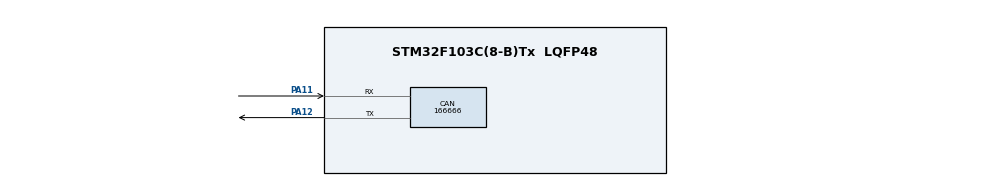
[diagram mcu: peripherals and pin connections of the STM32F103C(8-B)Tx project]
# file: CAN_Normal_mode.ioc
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CAN.CalculateBaudRate=166666
CAN.CalculateTimeBit=6000.00
CAN.CalculateTimeQuantum=2000.0
Mcu.Family=STM32F1
Mcu.Name=STM32F103C(8-B)Tx
Mcu.Package=LQFP48
NVIC.PriorityGroup=NVIC_PRIORITYGROUP_4
NVIC.TIM4_IRQn=true\:15\:0\:true\:false\:true\:true\:true
PA11.Mode=CAN_Activate
PA11.Signal=CAN_RX
PA12.Mode=CAN_Activate
PA12.Signal=CAN_TX
PA13.Mode=Serial_Wire
PA13.Signal=SYS_JTMS-SWDIO
PA14.Mode=Serial_Wire
PA14.Signal=SYS_JTCK-SWCLK
PC14-OSC32_IN.Mode=LSE-External-Oscillator
PC14-OSC32_IN.Signal=RCC_OSC32_IN
PC15-OSC32_OUT.Mode=LSE-External-Oscillator
PC15-OSC32_OUT.Signal=RCC_OSC32_OUT
PD0-OSC_IN.Mode=HSE-External-Oscillator
PD0-OSC_IN.Signal=RCC_OSC_IN
PD1-OSC_OUT.Mode=HSE-External-Oscillator
PD1-OSC_OUT.Signal=RCC_OSC_OUT
ProjectManager.HeapSize=0x200
ProjectManager.StackSize=0x400
ProjectManager.TargetToolchain=MDK-ARM V5.27
RCC.APB1Freq_Value=8000000
RCC.APB2Freq_Value=8000000
RCC.SYSCLKSource=RCC_SYSCLKSOURCE_HSE
TIM4.AutoReloadPreload=TIM_AUTORELOAD_PRELOAD_ENABLE
TIM4.Period=99
TIM4.Prescaler=7999
VP_TIM4_VS_ClockSourceINT.Mode=Internal
board=custom

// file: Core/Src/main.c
/* USER CODE BEGIN Header */
/**
  ******************************************************************************
  * @file           : main.c
  * @brief          : Main program body
  ******************************************************************************
  * @attention
  *
  * <h2><center>&copy; Copyright (c) 2021 STMicroelectronics.
  * All rights reserved.</center></h2>
  *
  * This software component is licensed by ST under BSD 3-Clause license,
  * the "License"; You may not use this file except in compliance with the
  * License. You may obtain a copy of the License at:
  *                        opensource.org/licenses/BSD-3-Clause
  *
  ******************************************************************************
  */
/* USER CODE END Header */
#include "main.h"
#include "can.h"
#include "tim.h"
#include "gpio.h"

/* USER CODE BEGIN PV */
volatile float g_timer_count = 0u;
volatile uint8_t led_no = 0u;
/* USER CODE END PV */

void SystemClock_Config(void);
/* USER CODE BEGIN PFP */
HAL_StatusTypeDef CAN_Transmit(void);
HAL_StatusTypeDef CAN_Filter_Config( void );
HAL_StatusTypeDef LED_manage_output( uint8_t led_no );
HAL_StatusTypeDef Send_response( uint32_t SidId );
HAL_StatusTypeDef CAN_Transmit_request(void);
/* USER CODE END PFP */

int main(void)
{

  /* MCU Configuration--------------------------------------------------------*/

  /* Reset of all peripherals, Initializes the Flash interface and the Systick. */
  HAL_Init();

  /* Configure the system clock */
  SystemClock_Config();

  /* Initialize all configured peripherals */
  MX_GPIO_Init();
  MX_CAN_Init();
  MX_TIM4_Init();
  /* USER CODE BEGIN 2 */
	HAL_TIM_Base_Start_IT(&htim4);

	CAN_Filter_Config();
	if( HAL_OK != HAL_CAN_ActivateNotification(&hcan, CAN_IT_TX_MAILBOX_EMPTY | CAN_IT_RX_FIFO0_MSG_PENDING | CAN_IT_BUSOFF)){
		Error_Handler();
	}
	if( HAL_OK != HAL_CAN_Start(&hcan)){ // put can in normal mode
		Error_Handler();
	}

  /* USER CODE END 2 */

  /* Infinite loop */
  while (1)
  {

  }
}

void SystemClock_Config(void)
{
  RCC_OscInitTypeDef RCC_OscInitStruct = {0};
  RCC_ClkInitTypeDef RCC_ClkInitStruct = {0};

  /** Initializes the RCC Oscillators according to the specified parameters
  * in the RCC_OscInitTypeDef structure.
  */
  RCC_OscInitStruct.OscillatorType = RCC_OSCILLATORTYPE_HSE;
  RCC_OscInitStruct.HSEState = RCC_HSE_ON;
  RCC_OscInitStruct.PLL.PLLState = RCC_PLL_NONE;
  if (HAL_RCC_OscConfig(&RCC_OscInitStruct) != HAL_OK)
  {
    Error_Handler();
  }
  /** Initializes the CPU, AHB and APB buses clocks
  */
  RCC_ClkInitStruct.ClockType = RCC_CLOCKTYPE_HCLK|RCC_CLOCKTYPE_SYSCLK
                              |RCC_CLOCKTYPE_PCLK1|RCC_CLOCKTYPE_PCLK2;
  RCC_ClkInitStruct.SYSCLKSource = RCC_SYSCLKSOURCE_HSE;
  RCC_ClkInitStruct.AHBCLKDivider = RCC_SYSCLK_DIV1;
  RCC_ClkInitStruct.APB1CLKDivider = RCC_HCLK_DIV1;
  RCC_ClkInitStruct.APB2CLKDivider = RCC_HCLK_DIV1;

  if (HAL_RCC_ClockConfig(&RCC_ClkInitStruct, FLASH_LATENCY_0) != HAL_OK)
  {
    Error_Handler();
  }

}

/* USER CODE BEGIN 4 */
void HAL_TIM_PeriodElapsedCallback(TIM_HandleTypeDef *htim)
{
  if( htim == &htim4 ){
		g_timer_count += 1u;
		if( 4u == g_timer_count){
			CAN_Transmit_request();
		}
		else{
			CAN_Transmit();
		}
	}
}

HAL_StatusTypeDef CAN_Transmit_request(void){
	uint8_t msg= 0u; // no meaning for data frame
	uint32_t mail_box;

	CAN_TxHeaderTypeDef Tx_header;
	Tx_header.DLC = 2u; // note(sender) request the receiver send 2bytes of reply
	Tx_header.IDE = CAN_ID_STD;
	Tx_header.StdId = 0x651;
	Tx_header.RTR = CAN_RTR_REMOTE;

	if( HAL_OK != HAL_CAN_AddTxMessage(&hcan, &Tx_header, &msg, &mail_box)){
		Error_Handler();
	}

	return HAL_OK;
}

HAL_StatusTypeDef CAN_Transmit(void){
	uint8_t msg= ++led_no;
	uint32_t mail_box;

	CAN_TxHeaderTypeDef Tx_header;
	Tx_header.DLC = 1u; // Transmit one bytes
	Tx_header.IDE = CAN_ID_STD;
	Tx_header.StdId = 0x65D;
	Tx_header.RTR = CAN_RTR_DATA;

	if( HAL_OK != HAL_CAN_AddTxMessage(&hcan, &Tx_header, &msg, &mail_box)){
		Error_Handler();
	}

	return HAL_OK;
}

HAL_StatusTypeDef CAN_Filter_Config( void ){
	CAN_FilterTypeDef Rx_filter_init;

	Rx_filter_init.FilterActivation = ENABLE;
	Rx_filter_init.FilterBank = 0U;
	Rx_filter_init.FilterFIFOAssignment = CAN_RX_FIFO0;
	Rx_filter_init.FilterIdHigh = 0x0000;
	Rx_filter_init.FilterIdLow = 0x0000;
	Rx_filter_init.FilterMaskIdHigh = 0x0000;
	Rx_filter_init.FilterMaskIdLow = 0x0000;
	Rx_filter_init.FilterMode = CAN_FILTERMODE_IDMASK;
	Rx_filter_init.FilterScale = CAN_FILTERSCALE_32BIT;

	HAL_CAN_ConfigFilter(&hcan, &Rx_filter_init);

	return HAL_OK;
}

void HAL_CAN_TxMailbox0CompleteCallback(CAN_HandleTypeDef *hcan){
  // completed transmition
}
void HAL_CAN_TxMailbox1CompleteCallback(CAN_HandleTypeDef *hcan){
	// completed transmition
}
void HAL_CAN_TxMailbox2CompleteCallback(CAN_HandleTypeDef *hcan){
	// completed transmition
}
void HAL_CAN_RxFifo0MsgPendingCallback(CAN_HandleTypeDef *hcan){
	CAN_RxHeaderTypeDef Rx_header;
	uint8_t buff[10u];

	/* get message into buff */
	if( HAL_OK != HAL_CAN_GetRxMessage(hcan, CAN_RX_FIFO0, &Rx_header, buff)){
		Error_Handler();
	}

	/* Filter message */
	if((Rx_header.StdId == 0x65D) && (Rx_header.RTR == 0u)){
		// data from note 1 to note 2
		LED_manage_output( buff[0] );
	}
	else if((Rx_header.StdId == 0x651) && (Rx_header.RTR == 1u)){
		// remote frame from note 1 to note 2
		Send_response(Rx_header.StdId);
	}
	else if((Rx_header.StdId == 0x651) && (Rx_header.RTR == 0u)){
		// this is the reply (data frame) by note 2 to note 1
	}

}
void HAL_CAN_ErrorCallback(CAN_HandleTypeDef *hcan){
	// error happen
}

HAL_StatusTypeDef LED_manage_output( uint8_t led_no ){
	switch(led_no){
		case 0:
			// turn led 0
			break;
		case 1u:
			// turn led 1
			break;
		default:
			break;
	}

	return HAL_OK;
}

HAL_StatusTypeDef Send_response( uint32_t SidId ){
	uint8_t msg[] = { 0xAB, 0xCD };
	uint32_t mail_box;

	CAN_TxHeaderTypeDef Tx_header;
	Tx_header.DLC = 2u; // Transmit one bytes
	Tx_header.IDE = CAN_ID_STD;
	Tx_header.StdId = SidId;
	Tx_header.RTR = CAN_RTR_DATA;

	if( HAL_OK != HAL_CAN_AddTxMessage(&hcan, &Tx_header, msg, &mail_box)){
		Error_Handler();
	}

	return HAL_OK;
}
/* USER CODE END 4 */

void Error_Handler(void)
{
  __disable_irq();
  while (1)
  {
  }
}

/************************ (C) COPYRIGHT STMicroelectronics *****END OF FILE****/
